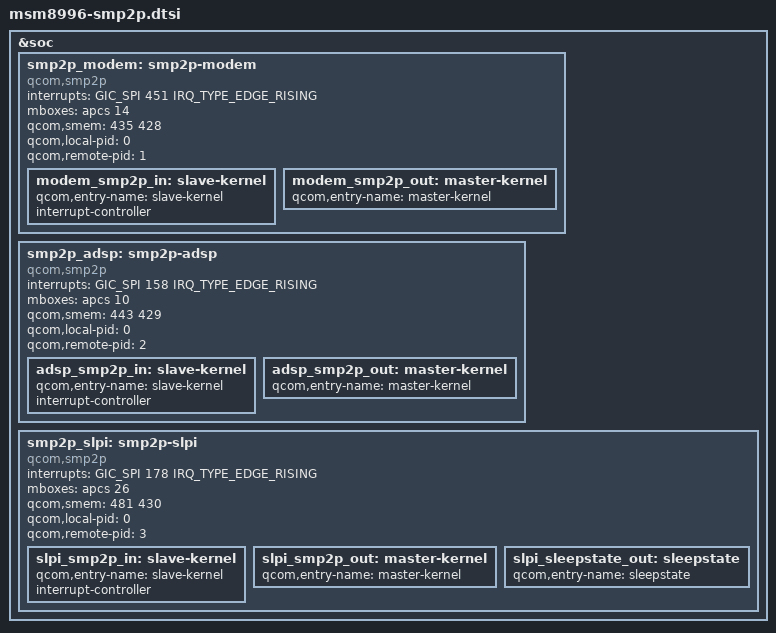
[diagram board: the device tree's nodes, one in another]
/* Copyright (c) 2014-2015, The Linux Foundation. All rights reserved.
 *
 * This program is free software; you can redistribute it and/or modify
 * it under the terms of the GNU General Public License version 2 and
 * only version 2 as published by the Free Software Foundation.
 *
 * This program is distributed in the hope that it will be useful,
 * but WITHOUT ANY WARRANTY; without even the implied warranty of
 * MERCHANTABILITY or FITNESS FOR A PARTICULAR PURPOSE.  See the
 * GNU General Public License for more details.
 */

#include <dt-bindings/interrupt-controller/arm-gic.h>

&soc {
	smp2p_modem: smp2p-modem {
		compatible = "qcom,smp2p";
		interrupts = <GIC_SPI 451 IRQ_TYPE_EDGE_RISING>;
		mboxes = <&apcs 14>;
		qcom,smem = <435 428>;
		qcom,local-pid = <0>;
		qcom,remote-pid = <1>;

		modem_smp2p_in: slave-kernel {
			qcom,entry-name = "slave-kernel";
			interrupt-controller;
			#interrupt-cells = <2>;
		};

		modem_smp2p_out: master-kernel {
			qcom,entry-name = "master-kernel";
			#qcom,smem-state-cells = <1>;
		};
	};

	smp2p_adsp: smp2p-adsp {
		compatible = "qcom,smp2p";
		interrupts = <GIC_SPI 158 IRQ_TYPE_EDGE_RISING>;
		mboxes = <&apcs 10>;
		qcom,smem = <443 429>;
		qcom,local-pid = <0>;
		qcom,remote-pid = <2>;

		adsp_smp2p_in: slave-kernel {
			qcom,entry-name = "slave-kernel";
			interrupt-controller;
			#interrupt-cells = <2>;
		};

		adsp_smp2p_out: master-kernel {
			qcom,entry-name = "master-kernel";
			#qcom,smem-state-cells = <1>;
		};
	};

	smp2p_slpi: smp2p-slpi {
		compatible = "qcom,smp2p";
		interrupts = <GIC_SPI 178 IRQ_TYPE_EDGE_RISING>;
		mboxes = <&apcs 26>;
		qcom,smem = <481 430>;
		qcom,local-pid = <0>;
		qcom,remote-pid = <3>;

		slpi_smp2p_in: slave-kernel {
			qcom,entry-name = "slave-kernel";
			interrupt-controller;
			#interrupt-cells = <2>;
		};

		slpi_smp2p_out: master-kernel {
			qcom,entry-name = "master-kernel";
			#qcom,smem-state-cells = <1>;
		};

		slpi_sleepstate_out: sleepstate {
			qcom,entry-name = "sleepstate";
			#qcom,smem-state-cells = <1>;
		};
	};
};
